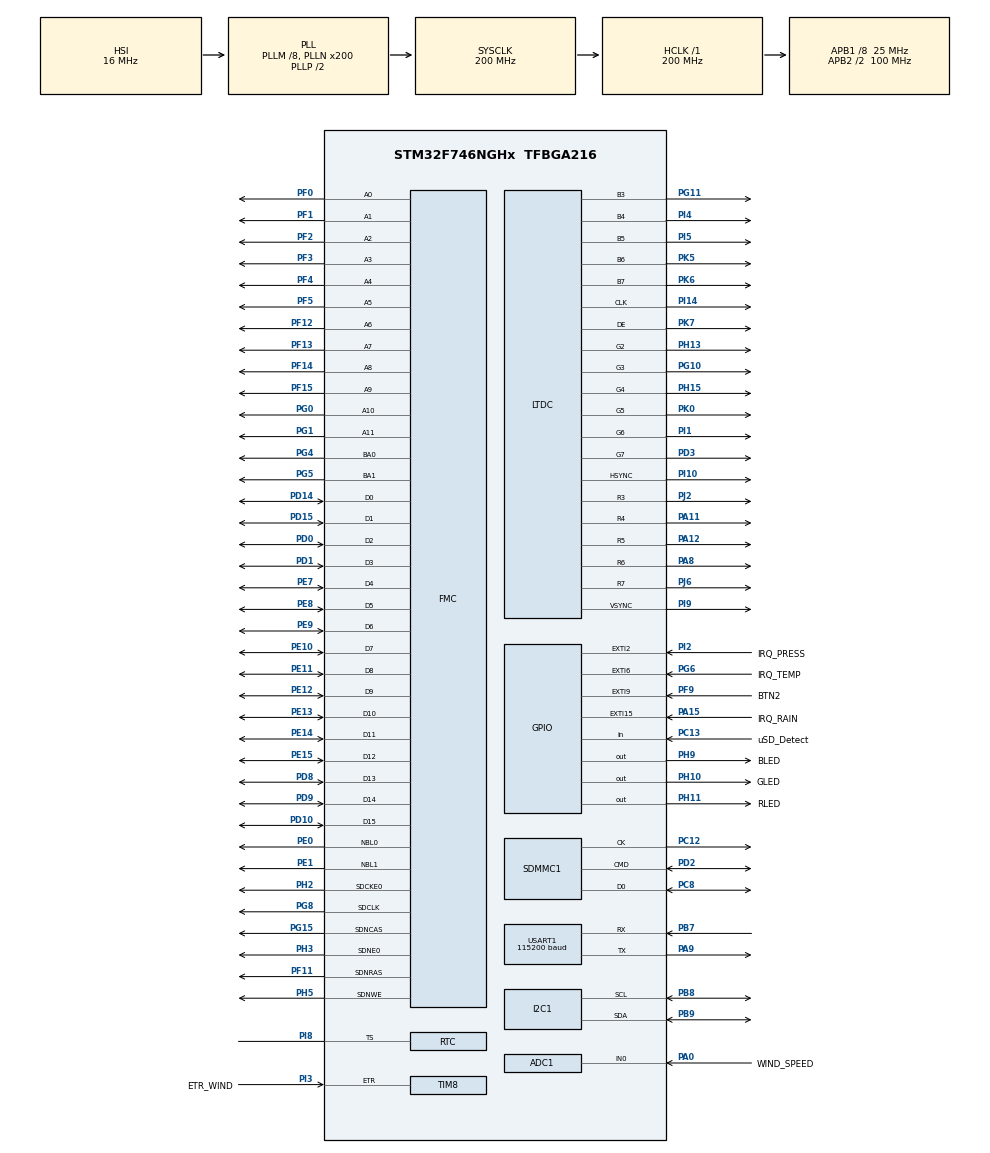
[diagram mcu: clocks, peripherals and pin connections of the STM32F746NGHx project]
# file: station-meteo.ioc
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ADC1.Channel-0\#ChannelRegularConversion=ADC_CHANNEL_0
ADC1.ContinuousConvMode=DISABLE
ADC1.DMAContinuousRequests=DISABLE
ADC1.NbrOfConversion=1
ADC1.NbrOfConversionFlag=1
ADC1.Rank-0\#ChannelRegularConversion=1
ADC1.SamplingTime-0\#ChannelRegularConversion=ADC_SAMPLETIME_3CYCLES
ADC1.ScanConvMode=ADC_SCAN_DISABLE
ADC1.master=1
CORTEX_M7.ART_ACCELERATOR_ENABLE=1
Dma.Request0=SDMMC1_RX
Dma.Request1=SDMMC1_TX
Dma.SDMMC1_RX.0.Direction=DMA_PERIPH_TO_MEMORY
Dma.SDMMC1_RX.0.FIFOMode=DMA_FIFOMODE_ENABLE
Dma.SDMMC1_RX.0.FIFOThreshold=DMA_FIFO_THRESHOLD_FULL
Dma.SDMMC1_RX.0.Instance=DMA2_Stream3
Dma.SDMMC1_RX.0.MemBurst=DMA_MBURST_INC4
Dma.SDMMC1_RX.0.MemDataAlignment=DMA_MDATAALIGN_WORD
Dma.SDMMC1_RX.0.MemInc=DMA_MINC_ENABLE
Dma.SDMMC1_RX.0.Mode=DMA_PFCTRL
Dma.SDMMC1_RX.0.PeriphBurst=DMA_PBURST_INC4
Dma.SDMMC1_RX.0.PeriphDataAlignment=DMA_PDATAALIGN_WORD
Dma.SDMMC1_RX.0.PeriphInc=DMA_PINC_DISABLE
Dma.SDMMC1_RX.0.Priority=DMA_PRIORITY_LOW
Dma.SDMMC1_TX.1.Direction=DMA_MEMORY_TO_PERIPH
Dma.SDMMC1_TX.1.FIFOMode=DMA_FIFOMODE_ENABLE
Dma.SDMMC1_TX.1.FIFOThreshold=DMA_FIFO_THRESHOLD_FULL
Dma.SDMMC1_TX.1.Instance=DMA2_Stream6
Dma.SDMMC1_TX.1.MemBurst=DMA_MBURST_INC4
Dma.SDMMC1_TX.1.MemDataAlignment=DMA_MDATAALIGN_WORD
Dma.SDMMC1_TX.1.MemInc=DMA_MINC_ENABLE
Dma.SDMMC1_TX.1.Mode=DMA_PFCTRL
Dma.SDMMC1_TX.1.PeriphBurst=DMA_PBURST_INC4
Dma.SDMMC1_TX.1.PeriphDataAlignment=DMA_PDATAALIGN_WORD
Dma.SDMMC1_TX.1.PeriphInc=DMA_PINC_DISABLE
Dma.SDMMC1_TX.1.Priority=DMA_PRIORITY_LOW
FATFS.BSP.number=1
FATFS.USE_DMA_CODE_SD=1
FATFS0.BSP.STBoard=false
FATFS0.BSP.api=Unknown
FATFS0.BSP.instance=PC13
FATFS0.BSP.ip=GPIO
FATFS0.BSP.mode=Input
FATFS0.BSP.name=Detect_SDIO
FATFS0.BSP.solution=PC13
I2C1.Timing=0x00606092
Mcu.Family=STM32F7
Mcu.Name=STM32F746NGHx
Mcu.Package=TFBGA216
NVIC.ADC_IRQn=true\:0\:0\:false\:false\:true\:true\:true\:true
NVIC.DMA2_Stream3_IRQn=true\:0\:0\:false\:false\:true\:false\:true\:true
NVIC.DMA2_Stream6_IRQn=true\:0\:0\:false\:false\:true\:false\:true\:true
NVIC.EXTI15_10_IRQn=true\:0\:0\:false\:false\:true\:true\:true\:true
NVIC.EXTI2_IRQn=true\:0\:0\:false\:false\:true\:true\:true\:true
NVIC.EXTI9_5_IRQn=true\:0\:0\:false\:false\:true\:true\:true\:true
NVIC.PriorityGroup=NVIC_PRIORITYGROUP_4
NVIC.RTC_Alarm_IRQn=true\:0\:0\:false\:false\:true\:true\:true\:true
NVIC.SDMMC1_IRQn=true\:0\:0\:false\:false\:true\:true\:true\:true
NVIC.TIM6_DAC_IRQn=true\:0\:0\:false\:false\:true\:true\:true\:true
NVIC.TIM7_IRQn=true\:0\:0\:false\:false\:true\:true\:true\:true
PA0/WKUP.GPIO_Label=WIND_SPEED
PA0/WKUP.Signal=ADCx_IN0
PA11.Mode=RGB565
PA11.Signal=LTDC_R4
PA12.Mode=RGB565
PA12.Signal=LTDC_R5
PA13.Mode=Serial_Wire
PA13.Signal=SYS_JTMS-SWDIO
PA14.Mode=Serial_Wire
PA14.Signal=SYS_JTCK-SWCLK
PA15.GPIO_Label=IRQ_RAIN
PA15.Signal=GPXTI15
PA8.Mode=RGB565
PA8.Signal=LTDC_R6
PA9.Mode=Asynchronous
PA9.Signal=USART1_TX
PB7.Mode=Asynchronous
PB7.Signal=USART1_RX
PB8.Mode=I2C
PB8.Signal=I2C1_SCL
PB9.Mode=I2C
PB9.Signal=I2C1_SDA
PC12.Mode=SD_1_bit
PC12.Signal=SDMMC1_CK
PC13.GPIO_Label=uSD_Detect
PC13.Signal=GPIO_Input
PC14/OSC32_IN.Mode=LSE-External-Oscillator
PC14/OSC32_IN.Signal=RCC_OSC32_IN
PC15/OSC32_OUT.Mode=LSE-External-Oscillator
PC15/OSC32_OUT.Signal=RCC_OSC32_OUT
PC8.Mode=SD_1_bit
PC8.Signal=SDMMC1_D0
PD0.Signal=FMC_D2_DA2
PD1.Signal=FMC_D3_DA3
PD10.Signal=FMC_D15_DA15
PD14.Signal=FMC_D0_DA0
PD15.Signal=FMC_D1_DA1
PD2.Mode=SD_1_bit
PD2.Signal=SDMMC1_CMD
PD3.Mode=RGB565
PD3.Signal=LTDC_G7
PD8.Signal=FMC_D13_DA13
PD9.Signal=FMC_D14_DA14
PE0.Signal=FMC_NBL0
PE1.Signal=FMC_NBL1
PE10.Signal=FMC_D7_DA7
PE11.Signal=FMC_D8_DA8
PE12.Signal=FMC_D9_DA9
PE13.Signal=FMC_D10_DA10
PE14.Signal=FMC_D11_DA11
PE15.Signal=FMC_D12_DA12
PE7.Signal=FMC_D4_DA4
PE8.Signal=FMC_D5_DA5
PE9.Signal=FMC_D6_DA6
PF0.Signal=FMC_A0
PF1.Signal=FMC_A1
PF11.Signal=FMC_SDNRAS
PF12.Signal=FMC_A6
PF13.Signal=FMC_A7
PF14.Signal=FMC_A8
PF15.Signal=FMC_A9
PF2.Signal=FMC_A2
PF3.Signal=FMC_A3
PF4.Signal=FMC_A4
PF5.Signal=FMC_A5
PF9.GPIO_Label=BTN2
PF9.GPIO_ModeDefaultEXTI=GPIO_MODE_IT_FALLING
PF9.Signal=GPXTI9
PG0.Signal=FMC_A10
PG1.Signal=FMC_A11
PG10.Mode=RGB565
PG10.Signal=LTDC_G3
PG11.Mode=RGB565
PG11.Signal=LTDC_B3
PG15.Signal=FMC_SDNCAS
PG4.Signal=FMC_A14_BA0
PG5.Signal=FMC_A15_BA1
PG6.GPIO_Label=IRQ_TEMP
PG6.Signal=GPXTI6
PG8.Signal=FMC_SDCLK
PH0/OSC_IN.Mode=HSE-External-Oscillator
PH0/OSC_IN.Signal=RCC_OSC_IN
PH1/OSC_OUT.Mode=HSE-External-Oscillator
PH1/OSC_OUT.Signal=RCC_OSC_OUT
PH10.GPIO_Label=GLED
PH10.Signal=GPIO_Output
PH11.GPIO_Label=RLED
PH11.Signal=GPIO_Output
PH13.Mode=RGB565
PH13.Signal=LTDC_G2
PH15.Mode=RGB565
PH15.Signal=LTDC_G4
PH2.Mode=SdramChipSelect1_1
PH2.Signal=FMC_SDCKE0
PH3.Mode=SdramChipSelect1_1
PH3.Signal=FMC_SDNE0
PH5.Signal=FMC_SDNWE
PH9.GPIO_Label=BLED
PH9.Signal=GPIO_Output
PI1.Mode=RGB565
PI1.Signal=LTDC_G6
PI10.Mode=RGB565
PI10.Signal=LTDC_HSYNC
PI14.Mode=RGB565
PI14.Signal=LTDC_CLK
PI2.GPIO_Label=IRQ_PRESS
PI2.Signal=GPXTI2
PI3.GPIO_Label=ETR_WIND
PI3.Signal=S_TIM8_ETR
PI4.Mode=RGB565
PI4.Signal=LTDC_B4
PI5.Mode=RGB565
PI5.Signal=LTDC_B5
PI8.Mode=Timestamp enabled - Input Enabled to TS
PI8.Signal=RTC_TS
PI9.Mode=RGB565
PI9.Signal=LTDC_VSYNC
PJ2.Mode=RGB565
PJ2.Signal=LTDC_R3
PJ6.Mode=RGB565
PJ6.Signal=LTDC_R7
PK0.Mode=RGB565
PK0.Signal=LTDC_G5
PK5.Mode=RGB565
PK5.Signal=LTDC_B6
PK6.Mode=RGB565
PK6.Signal=LTDC_B7
PK7.Mode=RGB565
PK7.Signal=LTDC_DE
ProjectManager.HeapSize=0x400
ProjectManager.StackSize=0x800
ProjectManager.TargetToolchain=STM32CubeIDE
RCC.AHBFreq_Value=200000000
RCC.APB1CLKDivider=RCC_HCLK_DIV8
RCC.APB1Freq_Value=25000000
RCC.APB1TimFreq_Value=50000000
RCC.APB2CLKDivider=RCC_HCLK_DIV2
RCC.APB2Freq_Value=100000000
RCC.APB2TimFreq_Value=200000000
RCC.CortexFreq_Value=200000000
RCC.HCLKFreq_Value=200000000
RCC.HSE_VALUE=25000000
RCC.HSI_VALUE=16000000
RCC.PLLM=8
RCC.PLLN=200
RCC.PLLQ=8
RCC.PLLSAIN=57
RCC.PLLSAIR=3
RCC.PLLSAIRDiv=RCC_PLLSAIDIVR_4
RCC.RTCClockSelection=RCC_RTCCLKSOURCE_LSE
RCC.SDMMCClockSelection=RCC_SDMMC1CLKSOURCE_CLK48
RCC.SYSCLKFreq_VALUE=200000000
RCC.SYSCLKSource=RCC_SYSCLKSOURCE_PLLCLK
RCC.USBFreq_Value=50000000
RCC.VCOOutputFreq_Value=400000000
RTC.Alarm-Alarm\ A=RTC_ALARM_A
SH.ADCx_IN0.0=ADC1_IN0,IN0
SH.FMC_A0.0=FMC_A0,12b-sda1
SH.FMC_A1.0=FMC_A1,12b-sda1
SH.FMC_A10.0=FMC_A10,12b-sda1
SH.FMC_A11.0=FMC_A11,12b-sda1
SH.FMC_A14_BA0.0=FMC_BA0,FourSdramBanks1
SH.FMC_A15_BA1.0=FMC_BA1,FourSdramBanks1
SH.FMC_A2.0=FMC_A2,12b-sda1
SH.FMC_A3.0=FMC_A3,12b-sda1
SH.FMC_A4.0=FMC_A4,12b-sda1
SH.FMC_A5.0=FMC_A5,12b-sda1
SH.FMC_A6.0=FMC_A6,12b-sda1
SH.FMC_A7.0=FMC_A7,12b-sda1
SH.FMC_A8.0=FMC_A8,12b-sda1
SH.FMC_A9.0=FMC_A9,12b-sda1
SH.FMC_D0_DA0.0=FMC_D0,sd-16b-d1
SH.FMC_D10_DA10.0=FMC_D10,sd-16b-d1
SH.FMC_D11_DA11.0=FMC_D11,sd-16b-d1
SH.FMC_D12_DA12.0=FMC_D12,sd-16b-d1
SH.FMC_D13_DA13.0=FMC_D13,sd-16b-d1
SH.FMC_D14_DA14.0=FMC_D14,sd-16b-d1
SH.FMC_D15_DA15.0=FMC_D15,sd-16b-d1
SH.FMC_D1_DA1.0=FMC_D1,sd-16b-d1
SH.FMC_D2_DA2.0=FMC_D2,sd-16b-d1
SH.FMC_D3_DA3.0=FMC_D3,sd-16b-d1
SH.FMC_D4_DA4.0=FMC_D4,sd-16b-d1
SH.FMC_D5_DA5.0=FMC_D5,sd-16b-d1
SH.FMC_D6_DA6.0=FMC_D6,sd-16b-d1
SH.FMC_D7_DA7.0=FMC_D7,sd-16b-d1
SH.FMC_D8_DA8.0=FMC_D8,sd-16b-d1
SH.FMC_D9_DA9.0=FMC_D9,sd-16b-d1
SH.FMC_NBL0.0=FMC_NBL0,Sd2ByteEnable1
SH.FMC_NBL1.0=FMC_NBL1,Sd2ByteEnable1
SH.FMC_SDCLK.0=FMC_SDCLK,12b-sda1
SH.FMC_SDNCAS.0=FMC_SDNCAS,12b-sda1
SH.FMC_SDNRAS.0=FMC_SDNRAS,12b-sda1
SH.FMC_SDNWE.0=FMC_SDNWE,12b-sda1
SH.S_TIM8_ETR.0=TIM8_ETR,ClockSourceETR_Mode2
TIM6.Period=5000-1
TIM6.Prescaler=1000-1
TIM7.Period=50000-1
TIM7.Prescaler=1000-1
TIM8.ClockFilter=15
USART1.BaudRate=115200
USART1.VirtualMode-Asynchronous=VM_ASYNC
VP_DMA2D_VS_DMA2D.Mode=DMA2D_Activate
VP_FATFS_VS_SDIO.Mode=SDIO
VP_RTC_VS_RTC_Activate.Mode=RTC_Enabled
VP_RTC_VS_RTC_Alarm_A_Intern.Mode=Alarm A
VP_RTC_VS_RTC_Calendar.Mode=RTC_Calendar
VP_TIM6_VS_ClockSourceINT.Mode=Enable_Timer
VP_TIM7_VS_ClockSourceINT.Mode=Enable_Timer
board=STM32F746G-DISCO

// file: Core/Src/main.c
/* USER CODE BEGIN Header */
/* USER CODE END Header */
#include "main.h"
#include "adc.h"
#include "dma.h"
#include "dma2d.h"
#include "fatfs.h"
#include "i2c.h"
#include "ltdc.h"
#include "rtc.h"
#include "sdmmc.h"
#include "tim.h"
#include "usart.h"
#include "gpio.h"
#include "fmc.h"

/* USER CODE BEGIN Includes */
#include <stdio.h>
#include <string.h>
#include "hts221_reg.h"
#include "lps22hh_reg.h"
#include "stm32746g_discovery.h"
#include "stm32746g_discovery_lcd.h"
#include "stm32746g_discovery_sdram.h"
#include "stm32746g_discovery_ts.h"
#include "user_def_screen.h"
#include "user_def_sdcard.h"
#include "user_def_sensors.h"
#include "user_def_rtc.h"

/* USER CODE END Includes */

/* USER CODE BEGIN PD */

//UART PRINTF Define
#ifdef __GNUC__
#define PUTCHAR_PROTOTYPE int __io_putchar(int ch)
#else
#define PUTCHAR_PROTOTYPE int fputc(int ch, FILE * f)
#endif /* __GNUC__ */
/* USER CODE END PD */

/* USER CODE BEGIN PV */

//SENSORS Variables
volatile uint8_t Flag_Measure = 0;
volatile uint8_t Flag_DataTHRdy = 0;
volatile uint8_t Flag_DataPressRdy = 0;
volatile uint8_t Flag_RainfallCounter = 0;
volatile uint8_t Flag_DataWDirRdy = 0;
volatile uint8_t Flag_Rainfall = 0;
uint8_t MesCpt = 0;

uint32_t RainfallCounter = 0;
uint32_t *RainfallCounterPtr = &RainfallCounter;

extern int index_HT;
extern int index_Pr;
extern int index_WS;
extern int index_WD;
extern int index_Rf;

//SCREEN Variables
volatile uint8_t SCREEN_InactivityCpt = 0;
volatile uint8_t SCREEN_State = 0;
volatile uint8_t Flag_UsBtn2 = 0;
volatile uint8_t Flag_TS = 0;
TS_StateTypeDef TS_State;
uint16_t TS_x, TS_y, TS_past_x, TS_past_y;
extern uint8_t currentScreen;

//SDCARD Variables
uint8_t Flag_SaveHT = 0;
uint8_t Flag_SavePr = 0;
uint8_t Flag_SaveWS = 0;
uint8_t Flag_SaveWD = 0;
uint8_t Flag_SaveRf = 0;

/* USER CODE END PV */

void SystemClock_Config(void);

int main(void) {

	/* MCU Configuration--------------------------------------------------------*/

	/* Reset of all peripherals, Initializes the Flash interface and the Systick. */
	HAL_Init();

	/* Configure the system clock */
	SystemClock_Config();

	/* Initialize all configured peripherals */
	MX_GPIO_Init();
	MX_DMA_Init();
	MX_TIM7_Init();
	MX_TIM8_Init();
	MX_ADC1_Init();
	MX_I2C1_Init();
	MX_USART1_UART_Init();
	MX_SDMMC1_SD_Init();
	MX_DMA2D_Init();
	MX_FMC_Init();
	MX_LTDC_Init();
	MX_FATFS_Init();
	MX_TIM6_Init();
	MX_RTC_Init();
	/* USER CODE BEGIN 2 */
	// --- STEP N°0 : Initialization -------------------------------------------
	printf("Initialization started : \r\n");

	//SENSORS Initialization
	printf("\n - Sensors \r\n");
	HAL_TIM_Base_Start_IT(&htim7);
	HAL_TIM_Base_Start(&htim8);
	SENSOR_lps22hh_Init();
	SENSOR_hts221_Init();
	printf("Done. \r\n");

	//SCREEN Initialization
	printf("\n - Screen \r\n");
	HAL_TIM_Base_Start_IT(&htim6);
	BSP_LCD_Init();
	Display_LCD_Init();
	Display_LCD_Pages(0);
	HAL_GPIO_WritePin(GLED_GPIO_Port, GLED_Pin, 1);
	HAL_GPIO_WritePin(RLED_GPIO_Port, RLED_Pin, 0);
	HAL_GPIO_WritePin(BLED_GPIO_Port, BLED_Pin, 0);
	SCREEN_State = 1;
	printf("Done. \r\n");

	printf("\n - Touch Screen \r\n");
	BSP_TS_Init(BSP_LCD_GetXSize(), BSP_LCD_GetYSize());
	BSP_TS_ResetTouchData(&TS_State);
	TS_x = TS_State.touchX[0];
	TS_y = TS_State.touchY[0];
	printf("Done. \r\n");

	//SDCARD Initialization
	printf("\n - SDCard \r\n");
	SDCARD_Init(); //Comment to test without SDCard insert.
	printf("Done. \r\n");

	// RTC Initialization
	printf("\n - RTC \r\n");
	RTC_Init();
	printf("Done. \r\n");

	printf("\n Initialization completed. \r\n");
	/* USER CODE END 2 */

	/* Infinite loop */
	/* USER CODE BEGIN WHILE */
	// --- STEP N°1 : Waiting for any Flag -------------------------------------
	while (1) {

		// --- STEP N°10 : Flag TS ---------------------------------------------
		if (Flag_TS == 1) {
			TS_past_x = TS_x;
			TS_past_y = TS_y;
			BSP_TS_GetState(&TS_State);
			TS_x = TS_State.touchX[0];
			TS_y = TS_State.touchY[0];

			// --- STEP N°12 : Compare TS with previous TS data
			if (TS_x != TS_past_x || TS_y != TS_past_y) {
				printf("\n - TouchScreen Triggered \r\n");

				// --- STEP N°11 : Power ON Screen
				if (SCREEN_State == 0) {
					printf("Screen ON \r\n");
					Display_LCD_ON();
					SCREEN_State = 1;
				}

				// --- STEP N°13 : Refresh Screen
				else if (SCREEN_State == 1) {
					TS_Actualization();
				}
				SCREEN_InactivityCpt = 0;
			}
			// --- STEP N°19 : Reset Flag TS
			Flag_TS = 0;
		}

		// --- STEP N°20 : Flag UserButton 2 -----------------------------------
		else if (Flag_UsBtn2 == 1) {
			printf("\n - Button Triggered \r\n");

			// --- STEP N°21 : Power ON Screen
			if (SCREEN_State == 0) {
				printf("Screen ON \r\n");
				Display_LCD_ON();
				SCREEN_State = 1;
			}
			// --- STEP N°29 : Reset Flag UserButton2
			Flag_UsBtn2 = 0;
		}

		// --- STEP N°30 & N°31 : Flag DataTHRdy -------------------------------
		else if (Flag_DataTHRdy == 1) {
			printf("Temperature & Humidity sensor OK \r\n");
			SENSOR_hts221_Read_Data();
			SENSOR_hts221_Add_Data();

			// --- STEP N°32 & N°33 : Screen Refresh
			if (currentScreen == 1 || currentScreen == 2) {
				Display_LCD_Pages(currentScreen);
			}
			// --- STEP N°39 : Reset Flag DataTHRdy
			Flag_DataTHRdy = 0;
		}

		// --- STEP N°40 & N°41 : Flag DataTHRdy -------------------------------
		else if (Flag_DataPressRdy == 1) {
			printf("Pressure sensor OK\r\n");
			SENSOR_lps22hh_Read_Data();
			SENSOR_lps22hh_Add_Data();

			// --- STEP N°42 : Screen Refresh
			if (currentScreen == 3) {
				Display_LCD_Pages(currentScreen);
			}
			// --- STEP N°49 : Reset Flag DataPressRdy
			Flag_DataPressRdy = 0;
		}

		// --- STEP N°50 & N°51 : Flag DataWDirRdy -----------------------------
		else if (Flag_DataWDirRdy == 1) {
			printf("Wind Direction sensor OK\r\n");
			SENSOR_WDir_Read_Data();
			SENSOR_WDir_Add_Data();

			// --- STEP N°52 : Screen Refresh
			if (currentScreen == 5) {
				Display_LCD_Pages(currentScreen);
			}
			// --- STEP N°59 : Reset Flag DataWDirRdy
			Flag_DataWDirRdy = 0;
		}

		// --- STEP N°60 & N°61 : Flag DataRfRdy -----------------------------
		else if (Flag_Rainfall == 1) {
			printf("Rainfall sensor OK\r\n");
			SENSOR_Rain_Read_Data(RainfallCounterPtr);
			SENSOR_Rain_Add_Data();

			// --- STEP N°62 : Screen Refresh
			if (currentScreen == 6) {
				Display_LCD_Pages(currentScreen);
			}
			// --- STEP N°69 : Reset Flag DataRfRdy
			Flag_Rainfall = 0;
		}

		// --- STEP N°70 : Flag Measure ----------------------------------------
		if (Flag_Measure == 1) {
			char buffer[20];
			RTC_Get_UTC_Timestamp(buffer);
			printf("Current time: %s\r\n", buffer);

			switch (MesCpt) {
			case 0:
				// --- STEP N°71 : Humidity & Temperature
				SENSOR_hts221_Start_Conversion();
				MesCpt = 1;
				break;
			case 1:
				// --- STEP N°72 : Pressure
				SENSOR_lps22hh_Start_Conversion();
				MesCpt = 2;
				break;
			case 2:
				// --- STEP N°73 & N°74 : Wind Speed
				SENSOR_WindSpeed_Read_Data();
				SENSOR_WindSpeed_Add_Data();

				// --- STEP N°75 : Screen Refresh
				if (currentScreen == 4) {
					Display_LCD_Pages(currentScreen);
				}
				MesCpt = 3;
				break;
			case 3:
				// --- STEP N°76 : Wind Direction
				SENSOR_WDir_Start_Conversion();
				MesCpt = 0;
				break;
			}
			// --- STEP N°79 : Reset Flag Measure
			Flag_Measure = 0;
		}

		// --- STEP N°80 to N°89 : Save HT in SDCard ---------------------------
		else if (index_HT >= 9) {
			Flag_SaveHT = 1;
			SDCARD_Actualization();
		}
		// --- STEP N°90 to N°99 : Save Pr in SDCard ---------------------------
		else if (index_Pr >= 9) {
			Flag_SavePr = 1;
			SDCARD_Actualization();
		}
		// --- STEP N°100 to N°109 : Save WS in SDCard -------------------------
		else if (index_WS >= 9) {
			Flag_SaveWS = 1;
			SDCARD_Actualization();
		}
		// --- STEP N°110 to N°119 : Save WD in SDCard -------------------------
		else if (index_WD >= 9) {
			Flag_SaveWD = 1;
			SDCARD_Actualization();
		}
		// --- STEP N°120 to N°129 : Save Rf in SDCard -------------------------
		else if (index_Rf >= 9) {
			Flag_SaveRf = 1;
			SDCARD_Actualization();
		}

		// --- STEP N°130 : Flag Inactivity ------------------------------------
		else if (SCREEN_InactivityCpt >= 31) {
			if (SCREEN_State == 1) {
				printf("Screen OFF \r\n");
				Display_LCD_OFF();
				SCREEN_State = 0;
			}
			// --- STEP N°139 : Reset Flag Inactivity
			SCREEN_InactivityCpt = 0;
		}

		// --- STEP N°2 : µP Sleep ---------------------------------------------
		else {
			HAL_SuspendTick();
			HAL_PWR_EnterSLEEPMode(PWR_MAINREGULATOR_ON, PWR_SLEEPENTRY_WFI);
		}
	}
	/* USER CODE END WHILE */

}

void SystemClock_Config(void) {
	RCC_OscInitTypeDef RCC_OscInitStruct = { 0 };
	RCC_ClkInitTypeDef RCC_ClkInitStruct = { 0 };

	/** Configure LSE Drive Capability
	 */
	HAL_PWR_EnableBkUpAccess();
	__HAL_RCC_LSEDRIVE_CONFIG(RCC_LSEDRIVE_LOW);

	/** Configure the main internal regulator output voltage
	 */
	__HAL_RCC_PWR_CLK_ENABLE();
	__HAL_PWR_VOLTAGESCALING_CONFIG(PWR_REGULATOR_VOLTAGE_SCALE1);

	/** Initializes the RCC Oscillators according to the specified parameters
	 * in the RCC_OscInitTypeDef structure.
	 */
	RCC_OscInitStruct.OscillatorType = RCC_OSCILLATORTYPE_HSI
			| RCC_OSCILLATORTYPE_LSE;
	RCC_OscInitStruct.LSEState = RCC_LSE_ON;
	RCC_OscInitStruct.HSIState = RCC_HSI_ON;
	RCC_OscInitStruct.HSICalibrationValue = RCC_HSICALIBRATION_DEFAULT;
	RCC_OscInitStruct.PLL.PLLState = RCC_PLL_ON;
	RCC_OscInitStruct.PLL.PLLSource = RCC_PLLSOURCE_HSI;
	RCC_OscInitStruct.PLL.PLLM = 8;
	RCC_OscInitStruct.PLL.PLLN = 200;
	RCC_OscInitStruct.PLL.PLLP = RCC_PLLP_DIV2;
	RCC_OscInitStruct.PLL.PLLQ = 8;
	if (HAL_RCC_OscConfig(&RCC_OscInitStruct) != HAL_OK) {
		Error_Handler();
	}

	/** Activate the Over-Drive mode
	 */
	if (HAL_PWREx_EnableOverDrive() != HAL_OK) {
		Error_Handler();
	}

	/** Initializes the CPU, AHB and APB buses clocks
	 */
	RCC_ClkInitStruct.ClockType = RCC_CLOCKTYPE_HCLK | RCC_CLOCKTYPE_SYSCLK
			| RCC_CLOCKTYPE_PCLK1 | RCC_CLOCKTYPE_PCLK2;
	RCC_ClkInitStruct.SYSCLKSource = RCC_SYSCLKSOURCE_PLLCLK;
	RCC_ClkInitStruct.AHBCLKDivider = RCC_SYSCLK_DIV1;
	RCC_ClkInitStruct.APB1CLKDivider = RCC_HCLK_DIV8;
	RCC_ClkInitStruct.APB2CLKDivider = RCC_HCLK_DIV2;

	if (HAL_RCC_ClockConfig(&RCC_ClkInitStruct, FLASH_LATENCY_6) != HAL_OK) {
		Error_Handler();
	}
}

/* USER CODE BEGIN 4 */
//UART PRINTF Declaration
PUTCHAR_PROTOTYPE {
	HAL_UART_Transmit(&huart1, (uint8_t*) &ch, 1, 100);
	return ch;
}

//HAL TIM PeriodElapsed Callback
void HAL_TIM_PeriodElapsedCallback(TIM_HandleTypeDef *htim) {
	HAL_ResumeTick();
	if (htim == &htim7) {
		printf("\n - Timer 7 Triggered \r\n");
		Flag_Measure = 1;
		SCREEN_InactivityCpt++;
	}
	if (htim == &htim6) {
		Flag_TS = 1;
	}
}

//GPIO EXTI Interruption Callback
void HAL_GPIO_EXTI_Callback(uint16_t GPIO_Pin) {
	HAL_ResumeTick();
	if (GPIO_Pin == IRQ_TEMP_Pin) {
		Flag_DataTHRdy = 1;
	}
	if (GPIO_Pin == IRQ_PRESS_Pin) {
		Flag_DataPressRdy = 1;
	}
	if (GPIO_Pin == IRQ_RAIN_Pin) {
		RainfallCounter++;
		Flag_Rainfall = 1;
	}
	if (GPIO_Pin == BTN2_Pin) {
		SCREEN_InactivityCpt = 0;
		Flag_UsBtn2 = 1;
	}
}

//HAL ADC Conversion Callback
void HAL_ADC_ConvCpltCallback(ADC_HandleTypeDef *hadc) {
	Flag_DataWDirRdy = 1;
}

void HAL_RTC_AlarmAEventCallback(RTC_HandleTypeDef *hrtc) {
	RainfallCounter = 0;
	Flag_Rainfall = 1;
	printf("Rainfall counter reset\r\n");
}
/* USER CODE END 4 */

void Error_Handler(void) {
	__disable_irq();
	while (1) {
	}
}
